# iostr911fa register map
Registers are 16-bit, access not given, no defined reset value unless marked. A register's access mark holds for its fields unless they carry their own. Addresses are absolute; registers are grouped by the start of their names; [hi:lo] are bit positions; {n}, {i} and the like mark numbered series; 'fields as' and 'values as' point back to an identical list.

## WDG
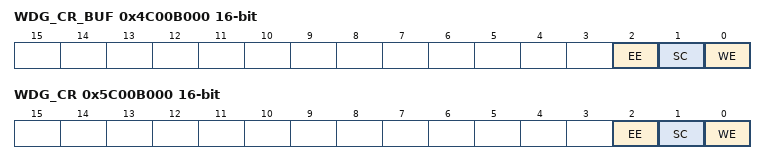
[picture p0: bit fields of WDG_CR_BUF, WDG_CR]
0x4C00B000 WDG_CR_BUF
  [2] EE, [1] SC, [0] WE
0x4C00B004 WDG_PR_BUF 8-bit
0x4C00B008 WDG_VR_BUF
0x4C00B00C WDG_CNT_BUF
0x4C00B010 WDG_SR_BUF
  [0] EC
0x4C00B014 WDG_MR_BUF
  [0] ECM
0x4C00B018 WDG_KR_BUF
0x5C00B000 WDG_CR
  [2] EE, [1] SC, [0] WE
0x5C00B004 WDG_PR 8-bit
0x5C00B008 WDG_VR
0x5C00B00C WDG_CNT
0x5C00B010 WDG_SR
  [0] EC
0x5C00B014 WDG_MR
  [0] ECM
0x5C00B018 WDG_KR

## TIM0
0x48002000 TIM0_IC1R_BUF
0x48002004 TIM0_IC2R_BUF
0x48002008 TIM0_OC1R_BUF
0x4800200C TIM0_OC2R_BUF
0x48002010 TIM0_CNTR_BUF
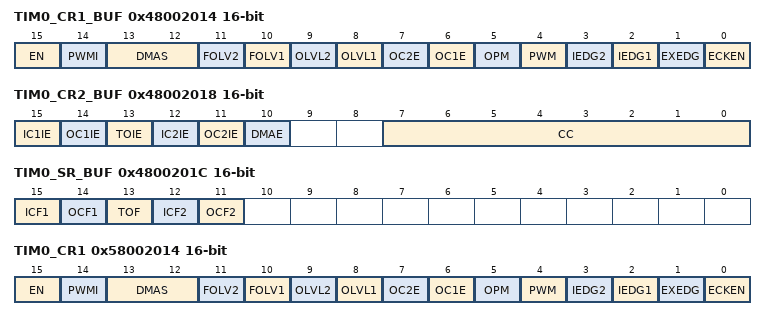
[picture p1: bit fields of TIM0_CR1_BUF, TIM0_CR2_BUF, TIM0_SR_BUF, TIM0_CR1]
0x48002014 TIM0_CR1_BUF
  [15] EN, [14] PWMI, [13:12] DMAS, [11] FOLV2, [10] FOLV1, [9] OLVL2, [8] OLVL1, [7] OC2E, [6] OC1E, [5] OPM, [4] PWM, [3] IEDG2, [2] IEDG1, [1] EXEDG, [0] ECKEN
0x48002018 TIM0_CR2_BUF
  [15] IC1IE, [14] OC1IE, [13] TOIE, [12] IC2IE, [11] OC2IE, [10] DMAE, [7:0] CC
0x4800201C TIM0_SR_BUF
  [15] ICF1, [14] OCF1, [13] TOF, [12] ICF2, [11] OCF2
0x58002000 TIM0_IC1R
0x58002004 TIM0_IC2R
0x58002008 TIM0_OC1R
0x5800200C TIM0_OC2R
0x58002010 TIM0_CNTR
0x58002014 TIM0_CR1
  fields as TIM0_CR1_BUF
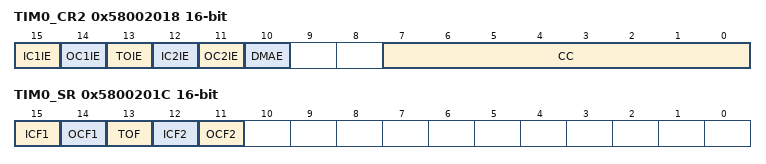
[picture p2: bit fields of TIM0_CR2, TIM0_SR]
0x58002018 TIM0_CR2
  fields as TIM0_CR2_BUF
0x5800201C TIM0_SR
  [15] ICF1, [14] OCF1, [13] TOF, [12] ICF2, [11] OCF2

## TIM1
0x48003000 TIM1_IC1R_BUF
0x48003004 TIM1_IC2R_BUF
0x48003008 TIM1_OC1R_BUF
0x4800300C TIM1_OC2R_BUF
0x48003010 TIM1_CNTR_BUF
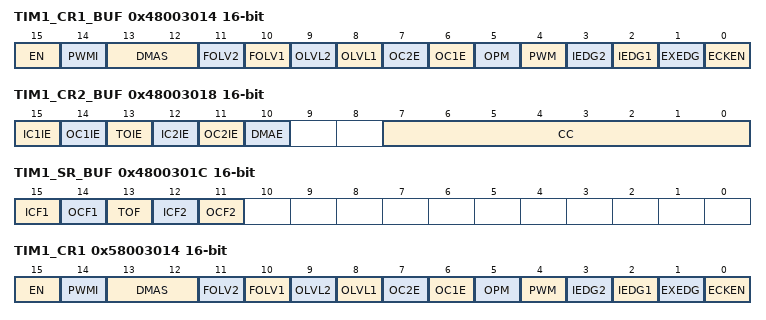
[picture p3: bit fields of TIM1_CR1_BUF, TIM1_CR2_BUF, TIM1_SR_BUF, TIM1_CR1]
0x48003014 TIM1_CR1_BUF
  [15] EN, [14] PWMI, [13:12] DMAS, [11] FOLV2, [10] FOLV1, [9] OLVL2, [8] OLVL1, [7] OC2E, [6] OC1E, [5] OPM, [4] PWM, [3] IEDG2, [2] IEDG1, [1] EXEDG, [0] ECKEN
0x48003018 TIM1_CR2_BUF
  [15] IC1IE, [14] OC1IE, [13] TOIE, [12] IC2IE, [11] OC2IE, [10] DMAE, [7:0] CC
0x4800301C TIM1_SR_BUF
  [15] ICF1, [14] OCF1, [13] TOF, [12] ICF2, [11] OCF2
0x58003000 TIM1_IC1R
0x58003004 TIM1_IC2R
0x58003008 TIM1_OC1R
0x5800300C TIM1_OC2R
0x58003010 TIM1_CNTR
0x58003014 TIM1_CR1
  fields as TIM1_CR1_BUF
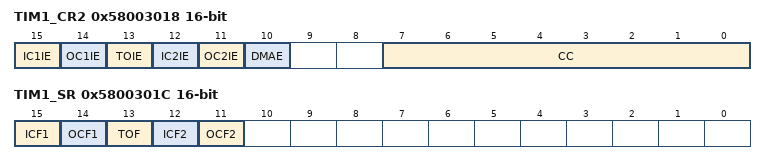
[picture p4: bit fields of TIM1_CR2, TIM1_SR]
0x58003018 TIM1_CR2
  fields as TIM1_CR2_BUF
0x5800301C TIM1_SR
  [15] ICF1, [14] OCF1, [13] TOF, [12] ICF2, [11] OCF2

## TIM2
0x48004000 TIM2_IC1R_BUF
0x48004004 TIM2_IC2R_BUF
0x48004008 TIM2_OC1R_BUF
0x4800400C TIM2_OC2R_BUF
0x48004010 TIM2_CNTR_BUF
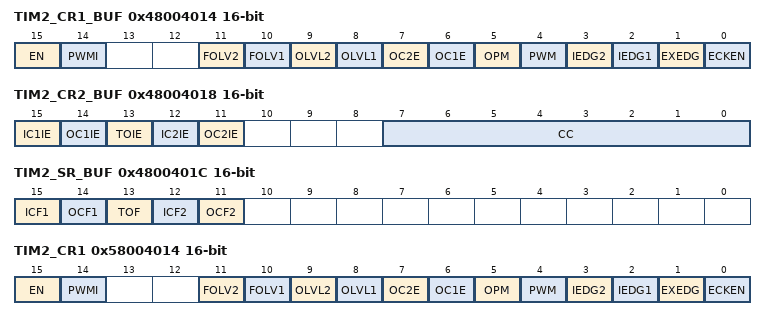
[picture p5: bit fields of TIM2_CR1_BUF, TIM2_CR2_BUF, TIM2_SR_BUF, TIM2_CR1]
0x48004014 TIM2_CR1_BUF
  [15] EN, [14] PWMI, [11] FOLV2, [10] FOLV1, [9] OLVL2, [8] OLVL1, [7] OC2E, [6] OC1E, [5] OPM, [4] PWM, [3] IEDG2, [2] IEDG1, [1] EXEDG, [0] ECKEN
0x48004018 TIM2_CR2_BUF
  [15] IC1IE, [14] OC1IE, [13] TOIE, [12] IC2IE, [11] OC2IE, [7:0] CC
0x4800401C TIM2_SR_BUF
  [15] ICF1, [14] OCF1, [13] TOF, [12] ICF2, [11] OCF2
0x58004000 TIM2_IC1R
0x58004004 TIM2_IC2R
0x58004008 TIM2_OC1R
0x5800400C TIM2_OC2R
0x58004010 TIM2_CNTR
0x58004014 TIM2_CR1
  fields as TIM2_CR1_BUF
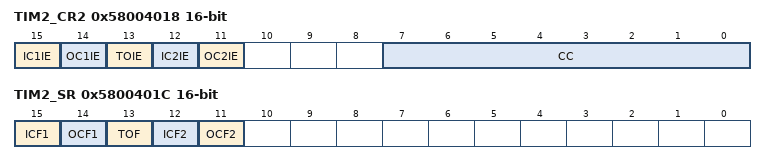
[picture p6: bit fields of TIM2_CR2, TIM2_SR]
0x58004018 TIM2_CR2
  [15] IC1IE, [14] OC1IE, [13] TOIE, [12] IC2IE, [11] OC2IE, [7:0] CC
0x5800401C TIM2_SR
  [15] ICF1, [14] OCF1, [13] TOF, [12] ICF2, [11] OCF2

## TIM3
0x48005000 TIM3_IC1R_BUF
0x48005004 TIM3_IC2R_BUF
0x48005008 TIM3_OC1R_BUF
0x4800500C TIM3_OC2R_BUF
0x48005010 TIM3_CNTR_BUF
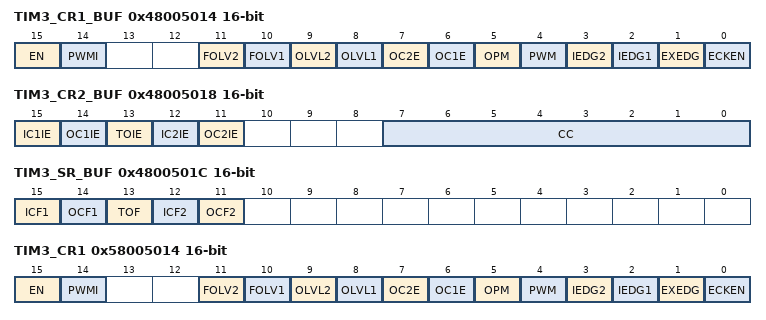
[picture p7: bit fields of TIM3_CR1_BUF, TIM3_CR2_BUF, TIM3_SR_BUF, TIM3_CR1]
0x48005014 TIM3_CR1_BUF
  [15] EN, [14] PWMI, [11] FOLV2, [10] FOLV1, [9] OLVL2, [8] OLVL1, [7] OC2E, [6] OC1E, [5] OPM, [4] PWM, [3] IEDG2, [2] IEDG1, [1] EXEDG, [0] ECKEN
0x48005018 TIM3_CR2_BUF
  [15] IC1IE, [14] OC1IE, [13] TOIE, [12] IC2IE, [11] OC2IE, [7:0] CC
0x4800501C TIM3_SR_BUF
  [15] ICF1, [14] OCF1, [13] TOF, [12] ICF2, [11] OCF2
0x58005000 TIM3_IC1R
0x58005004 TIM3_IC2R
0x58005008 TIM3_OC1R
0x5800500C TIM3_OC2R
0x58005010 TIM3_CNTR
0x58005014 TIM3_CR1
  fields as TIM3_CR1_BUF
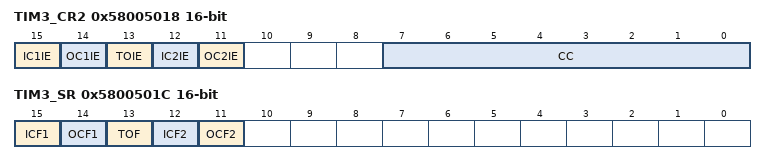
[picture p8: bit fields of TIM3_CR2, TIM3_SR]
0x58005018 TIM3_CR2
  [15] IC1IE, [14] OC1IE, [13] TOIE, [12] IC2IE, [11] OC2IE, [7:0] CC
0x5800501C TIM3_SR
  [15] ICF1, [14] OCF1, [13] TOF, [12] ICF2, [11] OCF2

## DMA
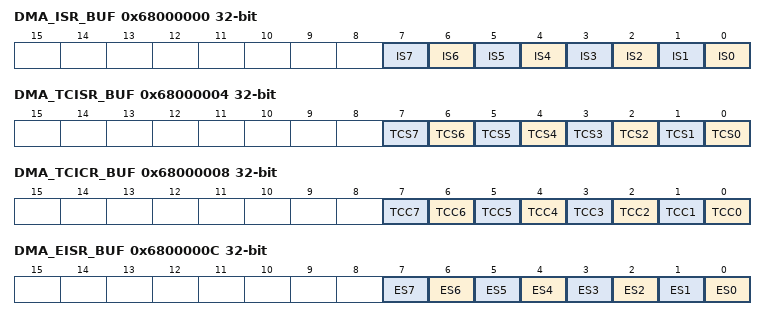
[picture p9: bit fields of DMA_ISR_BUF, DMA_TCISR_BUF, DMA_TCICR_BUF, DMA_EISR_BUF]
0x68000000 DMA_ISR_BUF 32-bit
  [n] IS{n} (n=0..7)
0x68000004 DMA_TCISR_BUF 32-bit
  [n] TCS{n} (n=0..7)
0x68000008 DMA_TCICR_BUF 32-bit
  [n] TCC{n} (n=0..7)
0x6800000C DMA_EISR_BUF 32-bit
  [n] ES{n} (n=0..7)
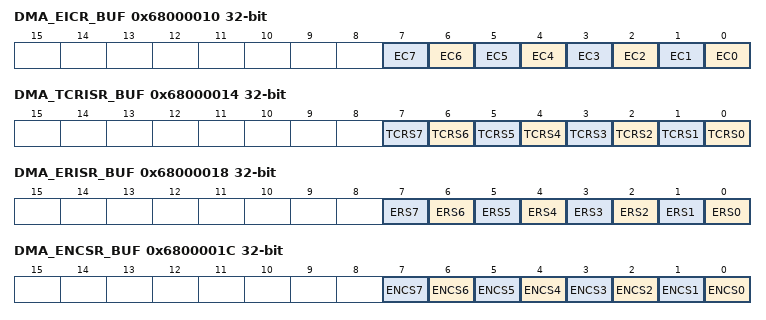
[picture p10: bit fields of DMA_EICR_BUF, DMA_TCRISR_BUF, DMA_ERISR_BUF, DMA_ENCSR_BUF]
0x68000010 DMA_EICR_BUF 32-bit
  [n] EC{n} (n=0..7)
0x68000014 DMA_TCRISR_BUF 32-bit
  [n] TCRS{n} (n=0..7)
0x68000018 DMA_ERISR_BUF 32-bit
  [n] ERS{n} (n=0..7)
0x6800001C DMA_ENCSR_BUF 32-bit
  [n] ENCS{n} (n=0..7)
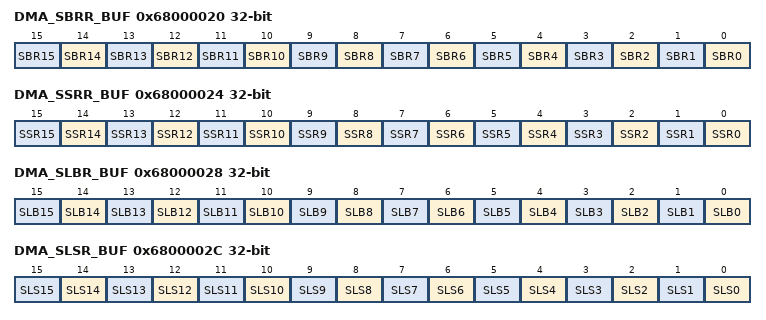
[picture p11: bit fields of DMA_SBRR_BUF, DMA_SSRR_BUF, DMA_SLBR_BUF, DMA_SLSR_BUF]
0x68000020 DMA_SBRR_BUF 32-bit
  [n] SBR{n} (n=0..15)
0x68000024 DMA_SSRR_BUF 32-bit
  [n] SSR{n} (n=0..15)
0x68000028 DMA_SLBR_BUF 32-bit
  [n] SLB{n} (n=0..15)
0x6800002C DMA_SLSR_BUF 32-bit
  [n] SLS{n} (n=0..15)
0x68000030 DMA_CNFR_BUF 32-bit
  [0] EN
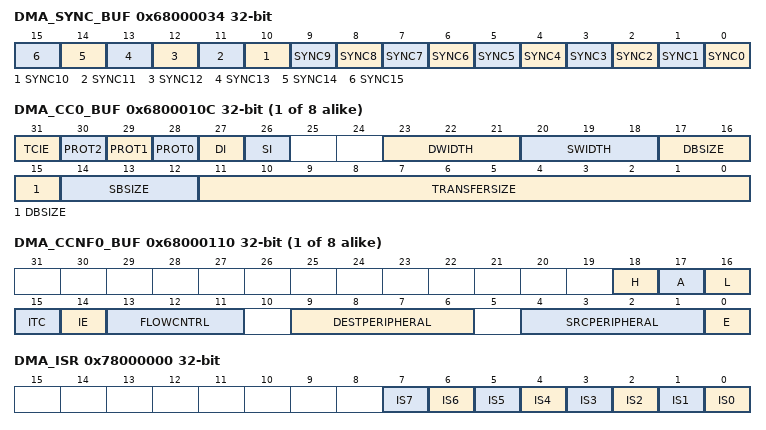
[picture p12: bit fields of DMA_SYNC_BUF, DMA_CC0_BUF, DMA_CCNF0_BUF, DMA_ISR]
0x68000034 DMA_SYNC_BUF 32-bit
  [n] SYNC{n} (n=0..15)
{0x68000100+0x20*i} DMA_SRC{i}_BUF 32-bit (i=0..7)
{0x68000104+0x20*i} DMA_DEST{i}_BUF 32-bit (i=0..7)
{0x68000108+0x20*i} DMA_LLI{i}_BUF 32-bit (i=0..7)
{0x6800010C+0x20*i} DMA_CC{i}_BUF 32-bit (i=0..7)
  [31] TCIE, [30] PROT2, [29] PROT1, [28] PROT0, [27] DI, [26] SI, [23:21] DWIDTH, [20:18] SWIDTH, [17:15] DBSIZE, [14:12] SBSIZE, [11:0] TRANSFERSIZE
{0x68000110+0x20*i} DMA_CCNF{i}_BUF 32-bit (i=0..7)
  [18] H, [17] A, [16] L, [15] ITC, [14] IE, [13:11] FLOWCNTRL, [9:6] DESTPERIPHERAL, [4:1] SRCPERIPHERAL, [0] E
0x78000000 DMA_ISR 32-bit
  [n] IS{n} (n=0..7)
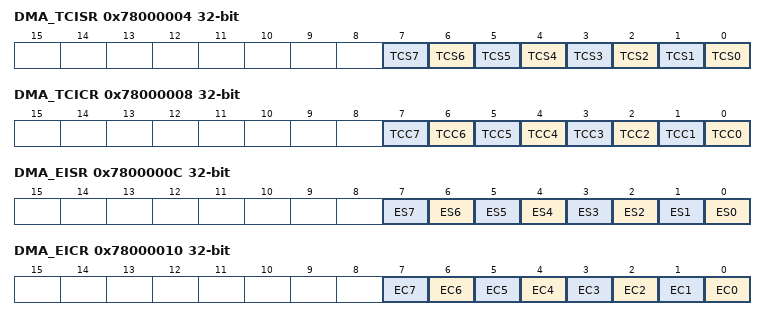
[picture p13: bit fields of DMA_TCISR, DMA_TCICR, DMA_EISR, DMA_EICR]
0x78000004 DMA_TCISR 32-bit
  [n] TCS{n} (n=0..7)
0x78000008 DMA_TCICR 32-bit
  [n] TCC{n} (n=0..7)
0x7800000C DMA_EISR 32-bit
  [n] ES{n} (n=0..7)
0x78000010 DMA_EICR 32-bit
  [n] EC{n} (n=0..7)
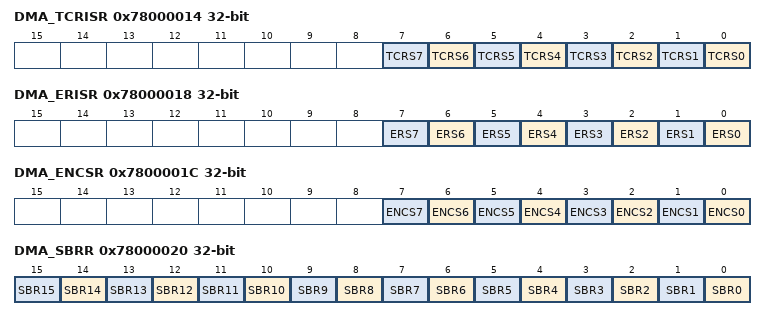
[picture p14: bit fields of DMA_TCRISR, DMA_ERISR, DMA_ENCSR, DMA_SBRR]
0x78000014 DMA_TCRISR 32-bit
  [n] TCRS{n} (n=0..7)
0x78000018 DMA_ERISR 32-bit
  [n] ERS{n} (n=0..7)
0x7800001C DMA_ENCSR 32-bit
  [n] ENCS{n} (n=0..7)
0x78000020 DMA_SBRR 32-bit
  [n] SBR{n} (n=0..15)
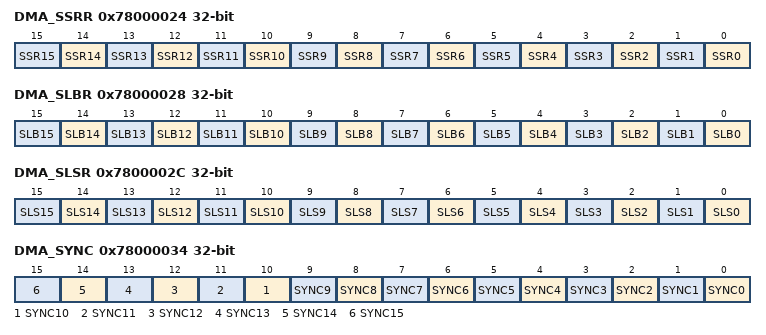
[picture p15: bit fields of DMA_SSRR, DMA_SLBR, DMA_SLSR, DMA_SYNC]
0x78000024 DMA_SSRR 32-bit
  [n] SSR{n} (n=0..15)
0x78000028 DMA_SLBR 32-bit
  [n] SLB{n} (n=0..15)
0x7800002C DMA_SLSR 32-bit
  [n] SLS{n} (n=0..15)
0x78000030 DMA_CNFR 32-bit
  [0] EN
0x78000034 DMA_SYNC 32-bit
  [n] SYNC{n} (n=0..15)
{0x78000100+0x20*i} DMA_SRC{i} 32-bit (i=0..7)
{0x78000104+0x20*i} DMA_DEST{i} 32-bit (i=0..7)
{0x78000108+0x20*i} DMA_LLI{i} 32-bit (i=0..7)
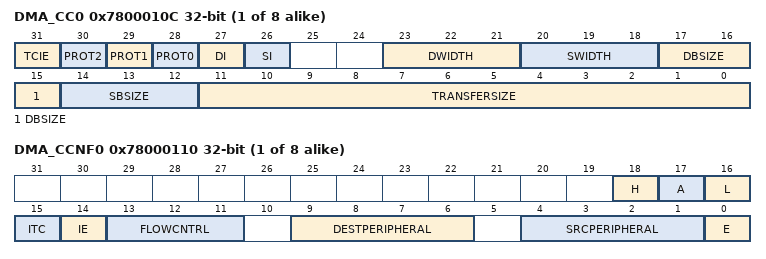
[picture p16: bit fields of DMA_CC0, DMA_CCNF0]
{0x7800010C+0x20*i} DMA_CC{i} 32-bit (i=0..7)
  fields as DMA_CC0_BUF
{0x78000110+0x20*i} DMA_CCNF{i} 32-bit (i=0..7)
  fields as DMA_CCNF0_BUF
